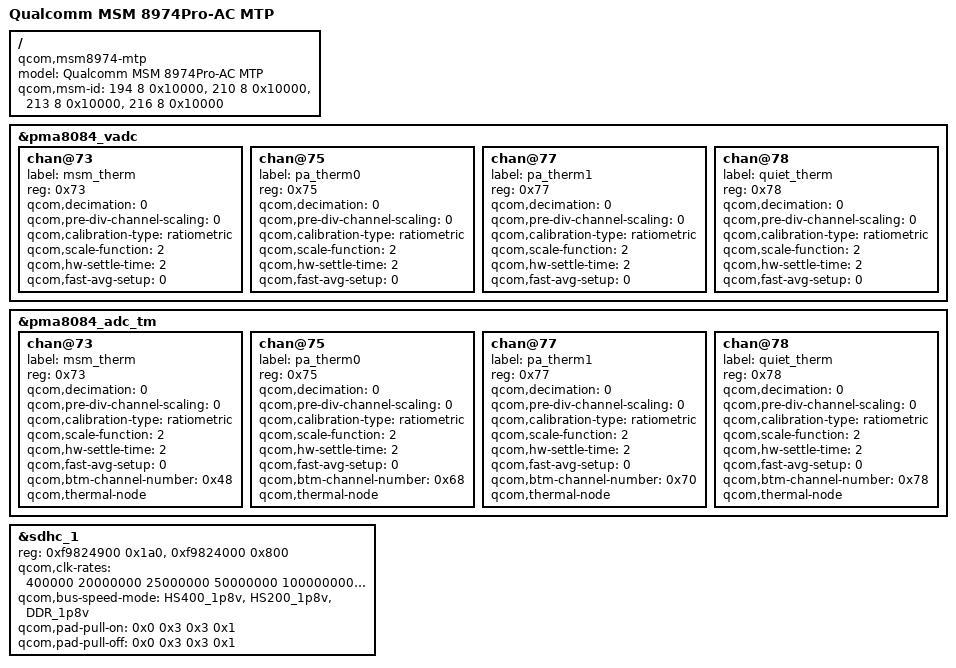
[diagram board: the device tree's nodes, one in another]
/* Copyright (c) 2013, The Linux Foundation. All rights reserved.
 *
 * This program is free software; you can redistribute it and/or modify
 * it under the terms of the GNU General Public License version 2 and
 * only version 2 as published by the Free Software Foundation.
 *
 * This program is distributed in the hope that it will be useful,
 * but WITHOUT ANY WARRANTY; without even the implied warranty of
 * MERCHANTABILITY or FITNESS FOR A PARTICULAR PURPOSE.  See the
 * GNU General Public License for more details.
 */

/dts-v1/;

/include/ "msm8974pro-ac-pm8941.dtsi"
/include/ "msm8974pro-ac-mtp.dtsi"

/ {
	model = "Qualcomm MSM 8974Pro-AC MTP";
	compatible = "qcom,msm8974-mtp", "qcom,msm8974", "qcom,mtp";
	qcom,msm-id = <194 8 0x10000>,
		      <210 8 0x10000>,
		      <213 8 0x10000>,
		      <216 8 0x10000>;
};

&pma8084_vadc {
	chan@73 {
		label = "msm_therm";
		reg = <0x73>;
		qcom,decimation = <0>;
		qcom,pre-div-channel-scaling = <0>;
		qcom,calibration-type = "ratiometric";
		qcom,scale-function = <2>;
		qcom,hw-settle-time = <2>;
		qcom,fast-avg-setup = <0>;
	};

	chan@75 {
		label = "pa_therm0";
		reg = <0x75>;
		qcom,decimation = <0>;
		qcom,pre-div-channel-scaling = <0>;
		qcom,calibration-type = "ratiometric";
		qcom,scale-function = <2>;
		qcom,hw-settle-time = <2>;
		qcom,fast-avg-setup = <0>;
	};

	chan@77 {
		label = "pa_therm1";
		reg = <0x77>;
		qcom,decimation = <0>;
		qcom,pre-div-channel-scaling = <0>;
		qcom,calibration-type = "ratiometric";
		qcom,scale-function = <2>;
		qcom,hw-settle-time = <2>;
		qcom,fast-avg-setup = <0>;
	};

	chan@78 {
		label = "quiet_therm";
		reg = <0x78>;
		qcom,decimation = <0>;
		qcom,pre-div-channel-scaling = <0>;
		qcom,calibration-type = "ratiometric";
		qcom,scale-function = <2>;
		qcom,hw-settle-time = <2>;
		qcom,fast-avg-setup = <0>;
	};
};

&pma8084_adc_tm {
	chan@73 {
		label = "msm_therm";
		reg = <0x73>;
		qcom,decimation = <0>;
		qcom,pre-div-channel-scaling = <0>;
		qcom,calibration-type = "ratiometric";
		qcom,scale-function = <2>;
		qcom,hw-settle-time = <2>;
		qcom,fast-avg-setup = <0>;
		qcom,btm-channel-number = <0x48>;
		qcom,thermal-node;
	};

	chan@75 {
		label = "pa_therm0";
		reg = <0x75>;
		qcom,decimation = <0>;
		qcom,pre-div-channel-scaling = <0>;
		qcom,calibration-type = "ratiometric";
		qcom,scale-function = <2>;
		qcom,hw-settle-time = <2>;
		qcom,fast-avg-setup = <0>;
		qcom,btm-channel-number = <0x68>;
		qcom,thermal-node;
	};

	chan@77 {
		label = "pa_therm1";
		reg = <0x77>;
		qcom,decimation = <0>;
		qcom,pre-div-channel-scaling = <0>;
		qcom,calibration-type = "ratiometric";
		qcom,scale-function = <2>;
		qcom,hw-settle-time = <2>;
		qcom,fast-avg-setup = <0>;
		qcom,btm-channel-number = <0x70>;
		qcom,thermal-node;
	};

	chan@78 {
		label = "quiet_therm";
		reg = <0x78>;
		qcom,decimation = <0>;
		qcom,pre-div-channel-scaling = <0>;
		qcom,calibration-type = "ratiometric";
		qcom,scale-function = <2>;
		qcom,hw-settle-time = <2>;
		qcom,fast-avg-setup = <0>;
		qcom,btm-channel-number = <0x78>;
		qcom,thermal-node;
	};
};

&sdhc_1 {
	reg = <0xf9824900 0x1a0>, <0xf9824000 0x800>;
	qcom,clk-rates = <400000 20000000 25000000 50000000 100000000 192000000 384000000>;
	qcom,bus-speed-mode = "HS400_1p8v", "HS200_1p8v", "DDR_1p8v";

	qcom,pad-pull-on = <0x0 0x3 0x3 0x1>; /* no-pull, pull-up, pull-up, pull-down */
	qcom,pad-pull-off = <0x0 0x3 0x3 0x1>; /* no-pull, pull-up, pull-up, pull-down */
};
